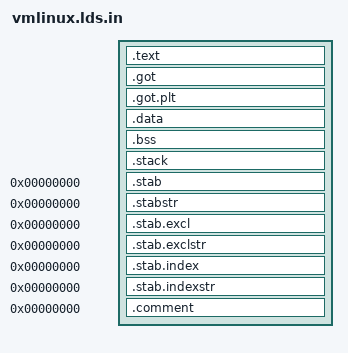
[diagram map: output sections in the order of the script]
/*
 * linux/arch/unicore/boot/compressed/vmlinux.lds.in
 *
 * Code specific to PKUnity SoC and UniCore ISA
 * Fragments that appear the same as the files in arm or x86
 *
 * Copyright (C) 2001-2008 GUAN Xue-tao
 *
 * This program is free software; you can redistribute it and/or modify
 * it under the terms of the GNU General Public License version 2 as
 * published by the Free Software Foundation.
 */
OUTPUT_ARCH(unicore32)
ENTRY(_start)
SECTIONS
{
  . = TEXT_START;
  _text = .;

  .text : {
    _start = .;
    *(.start)
    *(.text)
    *(.text.*)
    *(.fixup)
    *(.gnu.warning)
    *(.rodata)
    *(.rodata.*)
    *(.glue_7)
    *(.glue_7t)
    *(.piggydata)
    . = ALIGN(4);
  }

  _etext = .;

  _got_start = .;
  .got			: { *(.got) }
  _got_end = .;
  .got.plt		: { *(.got.plt) }
  .data			: { *(.data) }
  _edata = .;

  . = BSS_START;
  __bss_start = .;
  .bss			: { *(.bss) }
  _end = .;

  .stack (NOLOAD)	: { *(.stack) }

  .stab 0		: { *(.stab) }
  .stabstr 0		: { *(.stabstr) }
  .stab.excl 0		: { *(.stab.excl) }
  .stab.exclstr 0	: { *(.stab.exclstr) }
  .stab.index 0		: { *(.stab.index) }
  .stab.indexstr 0	: { *(.stab.indexstr) }
  .comment 0		: { *(.comment) }
}

